# DA1470x register map
Vendor: Dialog; Series: DA1470x; File version: 1.2
CPU: CM33 r0p2, little endian, MPU, FPU, DSP, VTOR, 4 interrupt priority bits
Registers are 32-bit, read-write, reset 0x0 unless marked. A register's access mark holds for its fields unless they carry their own. Offsets are from the block's base; [hi:lo] are bit positions.

## DSIDPHY_REG — DSIDPHY_REG registers
Base 0x51001500
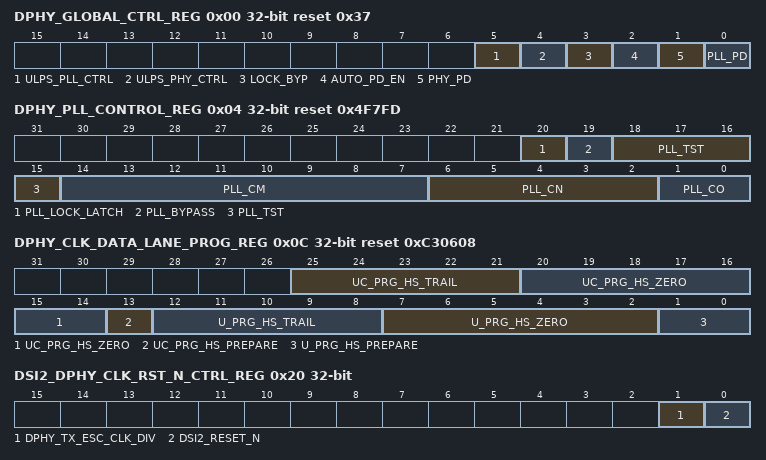
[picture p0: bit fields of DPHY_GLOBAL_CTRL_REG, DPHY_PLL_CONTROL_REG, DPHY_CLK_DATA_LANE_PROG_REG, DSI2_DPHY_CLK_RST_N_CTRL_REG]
0x00 DPHY_GLOBAL_CTRL_REG reset 0x37
  [5] ULPS_PLL_CTRL — When the PHY enters ULPS, this input determines if the PLL will be powered down or not. 1b0: Feature disabled 1b1: Feature enabled [Default]
  [4] ULPS_PHY_CTRL — When the PHY enters ULPS, this input determines if the PHY will be powered down or not. 1b0: Feature disabled 1b1: Feature enabled [Default]
  [3] LOCK_BYP — When clock lane exits from ULPS, this input determines if the PLL LOCK signal will be used to gate the TxByteClkHS 1b0: PLL LOCK signal will gate TxByteClkHS clock [Default] 1b1: PLL LOCK signal will not gate TxByteClkHS clock, CIL based counter will be used to gate the TxByteClkHS
  [2] AUTO_PD_EN — Powers down inactive lanes reported by CFG_NUM_LANES input bus. 1b0: inactive lanes are powered up and driving LP11. 1b1: inactive lanes are powered down [Default]
  [1] PHY_PD — Power Down input for PHY. When high, all blocks are powered down
  [0] PLL_PD — Power-down signal When high, the PLL is powered down
0x04 DPHY_PLL_CONTROL_REG reset 0x4F7FD — PLL control
  [20] PLL_LOCK_LATCH — Enable signal to use latched LOCK signal 1b0: LOCK<= Normal LOCK signal [Default] 1b1: LOCK<= Latched LOCK signal
  [19] PLL_BYPASS — Enable signal to bypass PLL: 1b0: CLKOUT<= CLKREF * ( M / ( N * O )) 1b1: CLKOUT<= CLKEXT
  [18:15] PLL_TST — Test Pins. Should be connected to chip configuration registers. 4'b1001: TST_PLL [Default] at normal operation
  [14:7] PLL_CM — Control M (feedback) divider
  [6:2] PLL_CN — Control N (input) divider
  [1:0] PLL_CO — Control O (output) divider
0x08 DPHY_STATUS_REG
  [0] PLL_LOCK ro — Lock Detect output. Asserted when PLL is frequency locked
0x0C DPHY_CLK_DATA_LANE_PROG_REG reset 0xC30608
  [25:21] UC_PRG_HS_TRAIL — Clock Lane: Bits used to program T_CLK_TRAIL time in the end of high speed transmission mode
  [20:14] UC_PRG_HS_ZERO — Clock Lane: Bits used to program T_CLK_ZERO time in the beginning of high speed transmission mode.
  [13] UC_PRG_HS_PREPARE — Clock Lane: Bit used to program T_CLK_PREPARE time in the beginning of high speed transmission mode.
  [12:8] U_PRG_HS_TRAIL — Data Lane: Bits used to program T_HS_TRAIL time in the end of high speed transmission mode
  [7:2] U_PRG_HS_ZERO — Data Lane: Bits used to program T_HS_ZERO time in the beginning of high speed transmission mode.
  [1:0] U_PRG_HS_PREPARE — Data Lane: Bits used to program T_HS_PREPARE time in the beginning of high speed transmission mode
0x10 DPHY_BIST_ENBL_REG
  [5:0] DPHY_BIST_ENBL — Six-bit signal that enables the testing modes [000000] Testing Disabled [000001] HS-TX Sequence Test (1) [000010] HS-TX Sequence Test (2) [000011] HS-TX Sequence PRBS Test (1) [000100] HS-TX Sequence PRBS Test (2) [001001] HS-TX Test (1) [001010] HS-TX Test (2) [001011] HS-TX PRBS Test (1) [001100] HS-TX PRBS Test (2) [001101] HS-TX SDI Test [010000] LP-TX LPDT Test [010001] LP-TX DC Test [010011] LP-RX DC Tests [010100] LP-CD DC Tests
0x14 DPHY_BIST_PATTERN_REG (reset mask 0x7FFFFFFF)
  [31:0] DPHY_BIST_PATTERN — This is the programmable test pattern used by BIST pattern generator and pattern matcher. The TEST_PATTERN bus value will be used as the payload data during the test, the HS SYNC token shouldnt be part of the TEST_PATTERN
0x18 DPHY_BIST_DC_OUT_REG
  [5:0] DPHY_BIST_DC_OUT ro — Output signal used in the DC test modes.
0x1C DPHY_TX_RCAL_REG — On-chip termination control
  [0] TX_RCAL — On-chip termination control bits for manual calibration of HS-TX. Only active when BYPASS_RCAL asserted. 1b0: 20% higher than mid-range. Highest impedance setting. 1b1: Mid-range impedance setting.
0x20 DSI2_DPHY_CLK_RST_N_CTRL_REG
  [1] DPHY_TX_ESC_CLK_DIV — 0: div/4, required with RCHS of 64MHz 1: div/6, required with RCHS of 92MHz
  [0] DSI2_RESET_N — Hold the DSI2 in reset. This should be set to 'b0 when configuring the DSI2 to avoid metastability
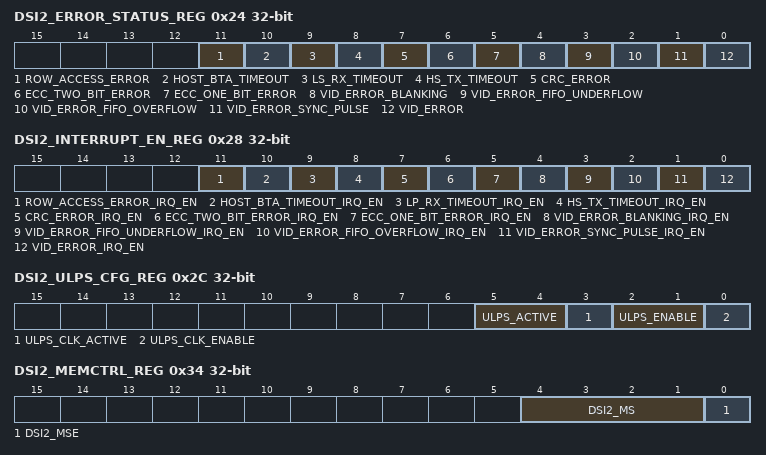
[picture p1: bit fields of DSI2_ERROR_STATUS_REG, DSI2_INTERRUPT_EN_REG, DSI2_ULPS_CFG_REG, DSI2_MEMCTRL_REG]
0x24 DSI2_ERROR_STATUS_REG
  [11] ROW_ACCESS_ERROR — There was a row access error in the memory. A read and a write took place at the same cycle. Reason could be that the FIFO was almost full
  [10] HOST_BTA_TIMEOUT — Host BTA timeout has occurred.
  [9] LS_RX_TIMEOUT — Low Power RX timeout has occurred
  [8] HS_TX_TIMEOUT — High Speed transmit has timed out.
  [7] CRC_ERROR — CRC calculated on the received data does not match the CRC the transmitter sent at the end of the packet.
  [6] ECC_TWO_BIT_ERROR — Single bit error in the packet header was detected and corrected.
  [5] ECC_ONE_BIT_ERROR — Two packet header bit errors were detected and not corrected
  [4] VID_ERROR_BLANKING — Only asserted if cfg_vid_video_mode is set to Burst Mode and cfg_vid_bllp_mode is set to 1b1. Asserted if not enough blanking time between end of a video line and the next vid_hsync. If video line transmission to the controller is occurring when a new vid_hsync is detected, this error signal will be asserted. This may indicate that VID_CLK is too fast, or that the cfg_vid_* parameters are incorrectly set.
  [3] VID_ERROR_FIFO_UNDERFLOW — Asserted if internal video FIFO underflows. The video rate might be lower than the MIPI rate. This may indicate that VID_CLK is too slow, or that the cfg_vid_* parameters are incorrectly set.
  [2] VID_ERROR_FIFO_OVERFLOW — Asserted if internal video FIFO overflows. The video rate might be higher than the MIPI rate or the delay for MIPI is long enough that the FIFO overflows. This may indicate that VID_CLK is too fast, or that the cfg_vid_* parameters are incorrectly set.
  [1] VID_ERROR_SYNC_PULSE — Only asserted if cfg_vid_video_mode is set to Non-Burst mode with Sync Pulses. New vid_hsync was detected while still sending blanking from last video line. This can occur if video rate is set to higher than MIPI rate and there is not enough cycles to transmit the video blanking after transmitting the video line. This may indicate that VID_CLK is too fast, or that the cfg_vid_* parameters are incorrectly set.
  [0] VID_ERROR — Asserted if an error occurs during operation. Signal is asserted if any of the other vid_error signals (sync_pulse, fifo_overflow, fifo_underflow, or blanking) are asserted. Signal can be used as an enable to latch the other vid_error signals.
0x28 DSI2_INTERRUPT_EN_REG
  [11] ROW_ACCESS_ERROR_IRQ_EN — Enable Row Access Error IRQ
  [10] HOST_BTA_TIMEOUT_IRQ_EN — Enable BTA timeout IRQ
  [9] LP_RX_TIMEOUT_IRQ_EN — Enable Low Power RX timeout IRQ
  [8] HS_TX_TIMEOUT_IRQ_EN — Enable High Speed TX timeout IRQ
  [7] CRC_ERROR_IRQ_EN — Enable CRC error IRQ
  [6] ECC_TWO_BIT_ERROR_IRQ_EN — Enable ECC 2 bit error IRQ
  [5] ECC_ONE_BIT_ERROR_IRQ_EN — Enable ECC 1 bit error IRQ
  [4] VID_ERROR_BLANKING_IRQ_EN — Enable VID blanking error IRQ
  [3] VID_ERROR_FIFO_UNDERFLOW_IRQ_EN — Enable VID FIFO underflow IRQ
  [2] VID_ERROR_FIFO_OVERFLOW_IRQ_EN — Enable VID FIFO overflow IRQ
  [1] VID_ERROR_SYNC_PULSE_IRQ_EN — Enable VID sync pulse error IRQ
  [0] VID_ERROR_IRQ_EN — Enable VID error IRQ
0x2C DSI2_ULPS_CFG_REG
  [5:4] ULPS_ACTIVE ro — Ultra Low Power State status. Bits assert high to indicate that the corresponding data lanes are in Ultra Low Power State. Bit [0] Data lane 0 Bit [1] Data Lane 1
  [3] ULPS_CLK_ACTIVE ro — Ultra Low Power State clock lane status. Asserted high to indicate that the clock lane is in Ultra Low Power State.
  [2:1] ULPS_ENABLE — Ultra-Low Power State enable. When asserted (active high) the controller instructs the PHY to put the corresponding data lane into Ultra Low Power State. Bit [0] Data lane 0 Bit [1] Data Lane 1
  [0] ULPS_CLK_ENABLE — Ultra-Low Power State enable for clock lane. When set (1'b1) the controller instructs the PHY to put the clock lane into Ultra Low Power State.
0x30 DSI2_TRIGGER_REG
  [1:0] TRIGGER_DATA write-once — Transmit trigger. The format of trigger_send is as follows: 1b00 = Trigger 0 (Reset-Trigger) 1b01 = Trigger 1 ([Reserved]) 1b10 = Trigger 2 ([Reserved]) 1b11 = Trigger 3 ([Reserved])
0x34 DSI2_MEMCTRL_REG
  [4:1] DSI2_MS, [0] DSI2_MSE
